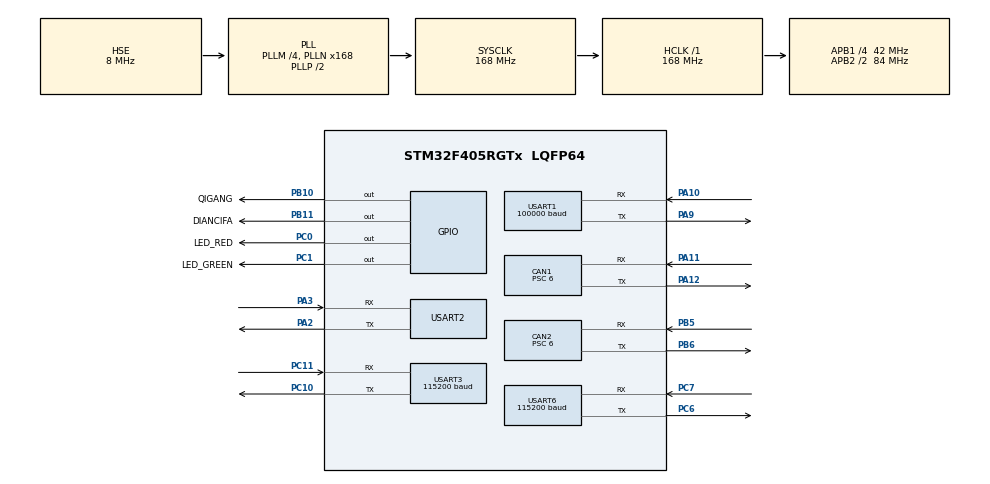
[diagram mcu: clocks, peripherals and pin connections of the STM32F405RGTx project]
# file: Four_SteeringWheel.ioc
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CAN1.BS1=CAN_BS1_3TQ
CAN1.BS2=CAN_BS2_3TQ
CAN1.CalculateBaudRate=1000000
CAN1.CalculateTimeBit=1000
CAN1.CalculateTimeQuantum=142.85714285714286
CAN1.Prescaler=6
CAN2.BS1=CAN_BS1_3TQ
CAN2.BS2=CAN_BS2_3TQ
CAN2.CalculateBaudRate=1000000
CAN2.CalculateTimeBit=1000
CAN2.CalculateTimeQuantum=142.85714285714286
CAN2.Prescaler=6
Dma.Request0=USART1_RX
Dma.Request1=USART2_RX
Dma.Request2=USART2_TX
Dma.Request3=USART3_RX
Dma.Request4=USART3_TX
Dma.Request5=USART6_RX
Dma.Request6=USART6_TX
Dma.USART1_RX.0.Direction=DMA_PERIPH_TO_MEMORY
Dma.USART1_RX.0.FIFOMode=DMA_FIFOMODE_DISABLE
Dma.USART1_RX.0.Instance=DMA2_Stream2
Dma.USART1_RX.0.MemDataAlignment=DMA_MDATAALIGN_BYTE
Dma.USART1_RX.0.MemInc=DMA_MINC_ENABLE
Dma.USART1_RX.0.Mode=DMA_CIRCULAR
Dma.USART1_RX.0.PeriphDataAlignment=DMA_PDATAALIGN_BYTE
Dma.USART1_RX.0.PeriphInc=DMA_PINC_DISABLE
Dma.USART1_RX.0.Priority=DMA_PRIORITY_LOW
Dma.USART2_RX.1.Direction=DMA_PERIPH_TO_MEMORY
Dma.USART2_RX.1.FIFOMode=DMA_FIFOMODE_DISABLE
Dma.USART2_RX.1.Instance=DMA1_Stream5
Dma.USART2_RX.1.MemDataAlignment=DMA_MDATAALIGN_BYTE
Dma.USART2_RX.1.MemInc=DMA_MINC_ENABLE
Dma.USART2_RX.1.Mode=DMA_CIRCULAR
Dma.USART2_RX.1.PeriphDataAlignment=DMA_PDATAALIGN_BYTE
Dma.USART2_RX.1.PeriphInc=DMA_PINC_DISABLE
Dma.USART2_RX.1.Priority=DMA_PRIORITY_LOW
Dma.USART2_TX.2.Direction=DMA_MEMORY_TO_PERIPH
Dma.USART2_TX.2.FIFOMode=DMA_FIFOMODE_DISABLE
Dma.USART2_TX.2.Instance=DMA1_Stream6
Dma.USART2_TX.2.MemDataAlignment=DMA_MDATAALIGN_BYTE
Dma.USART2_TX.2.MemInc=DMA_MINC_ENABLE
Dma.USART2_TX.2.Mode=DMA_CIRCULAR
Dma.USART2_TX.2.PeriphDataAlignment=DMA_PDATAALIGN_BYTE
Dma.USART2_TX.2.PeriphInc=DMA_PINC_DISABLE
Dma.USART2_TX.2.Priority=DMA_PRIORITY_LOW
Dma.USART3_RX.3.Direction=DMA_PERIPH_TO_MEMORY
Dma.USART3_RX.3.FIFOMode=DMA_FIFOMODE_DISABLE
Dma.USART3_RX.3.Instance=DMA1_Stream1
Dma.USART3_RX.3.MemDataAlignment=DMA_MDATAALIGN_BYTE
Dma.USART3_RX.3.MemInc=DMA_MINC_ENABLE
Dma.USART3_RX.3.Mode=DMA_CIRCULAR
Dma.USART3_RX.3.PeriphDataAlignment=DMA_PDATAALIGN_BYTE
Dma.USART3_RX.3.PeriphInc=DMA_PINC_DISABLE
Dma.USART3_RX.3.Priority=DMA_PRIORITY_LOW
Dma.USART3_TX.4.Direction=DMA_MEMORY_TO_PERIPH
Dma.USART3_TX.4.FIFOMode=DMA_FIFOMODE_DISABLE
Dma.USART3_TX.4.Instance=DMA1_Stream3
Dma.USART3_TX.4.MemDataAlignment=DMA_MDATAALIGN_BYTE
Dma.USART3_TX.4.MemInc=DMA_MINC_ENABLE
Dma.USART3_TX.4.Mode=DMA_CIRCULAR
Dma.USART3_TX.4.PeriphDataAlignment=DMA_PDATAALIGN_BYTE
Dma.USART3_TX.4.PeriphInc=DMA_PINC_DISABLE
Dma.USART3_TX.4.Priority=DMA_PRIORITY_LOW
Dma.USART6_RX.5.Direction=DMA_PERIPH_TO_MEMORY
Dma.USART6_RX.5.FIFOMode=DMA_FIFOMODE_DISABLE
Dma.USART6_RX.5.Instance=DMA2_Stream1
Dma.USART6_RX.5.MemDataAlignment=DMA_MDATAALIGN_BYTE
Dma.USART6_RX.5.MemInc=DMA_MINC_ENABLE
Dma.USART6_RX.5.Mode=DMA_CIRCULAR
Dma.USART6_RX.5.PeriphDataAlignment=DMA_PDATAALIGN_BYTE
Dma.USART6_RX.5.PeriphInc=DMA_PINC_DISABLE
Dma.USART6_RX.5.Priority=DMA_PRIORITY_LOW
Dma.USART6_TX.6.Direction=DMA_MEMORY_TO_PERIPH
Dma.USART6_TX.6.FIFOMode=DMA_FIFOMODE_DISABLE
Dma.USART6_TX.6.Instance=DMA2_Stream6
Dma.USART6_TX.6.MemDataAlignment=DMA_MDATAALIGN_BYTE
Dma.USART6_TX.6.MemInc=DMA_MINC_ENABLE
Dma.USART6_TX.6.Mode=DMA_CIRCULAR
Dma.USART6_TX.6.PeriphDataAlignment=DMA_PDATAALIGN_BYTE
Dma.USART6_TX.6.PeriphInc=DMA_PINC_DISABLE
Dma.USART6_TX.6.Priority=DMA_PRIORITY_LOW
Mcu.Family=STM32F4
Mcu.Name=STM32F405RGTx
Mcu.Package=LQFP64
NVIC.CAN1_RX0_IRQn=true\:5\:0\:true\:false\:true\:true\:true
NVIC.CAN2_RX0_IRQn=true\:5\:0\:true\:false\:true\:true\:true
NVIC.DMA1_Stream1_IRQn=true\:0\:0\:false\:false\:true\:false\:true
NVIC.DMA1_Stream3_IRQn=true\:0\:0\:false\:false\:true\:false\:true
NVIC.DMA1_Stream5_IRQn=true\:0\:0\:false\:false\:true\:false\:true
NVIC.DMA1_Stream6_IRQn=true\:0\:0\:false\:false\:true\:false\:true
NVIC.DMA2_Stream1_IRQn=true\:0\:0\:false\:false\:true\:false\:true
NVIC.DMA2_Stream2_IRQn=true\:0\:0\:false\:false\:true\:false\:true
NVIC.DMA2_Stream6_IRQn=true\:0\:0\:false\:false\:true\:false\:true
NVIC.PriorityGroup=NVIC_PRIORITYGROUP_4
NVIC.TIM2_IRQn=true\:5\:0\:true\:false\:true\:true\:true
NVIC.USART1_IRQn=true\:0\:0\:true\:false\:true\:true\:true
NVIC.USART2_IRQn=true\:5\:0\:true\:false\:true\:true\:true
NVIC.USART3_IRQn=true\:0\:0\:false\:false\:true\:true\:true
NVIC.USART6_IRQn=true\:0\:0\:false\:false\:true\:true\:true
PA10.Mode=Asynchronous
PA10.Signal=USART1_RX
PA11.Mode=CAN_Activate
PA11.Signal=CAN1_RX
PA12.Mode=CAN_Activate
PA12.Signal=CAN1_TX
PA13.Mode=Serial_Wire
PA13.Signal=SYS_JTMS-SWDIO
PA14.Mode=Serial_Wire
PA14.Signal=SYS_JTCK-SWCLK
PA2.Mode=Asynchronous
PA2.Signal=USART2_TX
PA3.Mode=Asynchronous
PA3.Signal=USART2_RX
PA9.Mode=Asynchronous
PA9.Signal=USART1_TX
PB10.GPIO_Label=QIGANG
PB10.GPIO_PuPd=GPIO_PULLUP
PB10.Signal=GPIO_Output
PB11.GPIO_Label=DIANCIFA
PB11.GPIO_PuPd=GPIO_PULLUP
PB11.Signal=GPIO_Output
PB5.Mode=CAN_Activate
PB5.Signal=CAN2_RX
PB6.Mode=CAN_Activate
PB6.Signal=CAN2_TX
PC0.GPIO_Label=LED_RED
PC0.GPIO_PuPd=GPIO_PULLUP
PC0.Signal=GPIO_Output
PC1.GPIO_Label=LED_GREEN
PC1.GPIO_PuPd=GPIO_PULLUP
PC1.Signal=GPIO_Output
PC10.Mode=Asynchronous
PC10.Signal=USART3_TX
PC11.Mode=Asynchronous
PC11.Signal=USART3_RX
PC6.Mode=Asynchronous
PC6.Signal=USART6_TX
PC7.Mode=Asynchronous
PC7.Signal=USART6_RX
PH0-OSC_IN.Mode=HSE-External-Oscillator
PH0-OSC_IN.Signal=RCC_OSC_IN
PH1-OSC_OUT.Mode=HSE-External-Oscillator
PH1-OSC_OUT.Signal=RCC_OSC_OUT
ProjectManager.HeapSize=0x200
ProjectManager.StackSize=0x400
ProjectManager.TargetToolchain=MDK-ARM V5.27
RCC.48MHZClocksFreq_Value=84000000
RCC.AHBFreq_Value=168000000
RCC.APB1CLKDivider=RCC_HCLK_DIV4
RCC.APB1Freq_Value=42000000
RCC.APB1TimFreq_Value=84000000
RCC.APB2CLKDivider=RCC_HCLK_DIV2
RCC.APB2Freq_Value=84000000
RCC.APB2TimFreq_Value=168000000
RCC.CortexFreq_Value=168000000
RCC.HCLKFreq_Value=168000000
RCC.HSE_VALUE=8000000
RCC.HSI_VALUE=16000000
RCC.LSE_VALUE=32768
RCC.PLLM=4
RCC.PLLN=168
RCC.PLLSourceVirtual=RCC_PLLSOURCE_HSE
RCC.SYSCLKFreq_VALUE=168000000
RCC.SYSCLKSource=RCC_SYSCLKSOURCE_PLLCLK
RCC.VCOOutputFreq_Value=336000000
TIM2.Period=1000-1
TIM2.Prescaler=84-1
USART1.BaudRate=100000
USART1.Parity=PARITY_EVEN
USART1.VirtualMode=VM_ASYNC
USART1.WordLength=WORDLENGTH_9B
USART2.VirtualMode=VM_ASYNC
USART3.BaudRate=115200
USART3.VirtualMode=VM_ASYNC
USART6.BaudRate=115200
USART6.VirtualMode=VM_ASYNC
VP_TIM2_VS_ClockSourceINT.Mode=Internal
board=custom

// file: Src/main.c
/* USER CODE BEGIN Header */
/**
  ******************************************************************************
  * @file           : main.c
  * @brief          : Main program body
  ******************************************************************************
  * @attention
  *
  * <h2><center>&copy; Copyright (c) 2021 STMicroelectronics.
  * All rights reserved.</center></h2>
  *
  * This software component is licensed by ST under BSD 3-Clause license,
  * the "License"; You may not use this file except in compliance with the
  * License. You may obtain a copy of the License at:
  *                        opensource.org/licenses/BSD-3-Clause
  *
  ******************************************************************************
  */
/* USER CODE END Header */
#include "main.h"
#include "can.h"
#include "dma.h"
#include "tim.h"
#include "usart.h"
#include "gpio.h"

/* USER CODE BEGIN Includes */
#include "math.h"
#include "Chassis_task.h"
/* USER CODE END Includes */

void SystemClock_Config(void);

int main(void)
{
  /* USER CODE BEGIN 1 */
extern uint8_t led_data[8];
  /* USER CODE END 1 */

  /* MCU Configuration--------------------------------------------------------*/

  /* Reset of all peripherals, Initializes the Flash interface and the Systick. */
  HAL_Init();

  /* Configure the system clock */
  SystemClock_Config();

  /* Initialize all configured peripherals */
  MX_GPIO_Init();
  MX_DMA_Init();
  MX_CAN1_Init();
  MX_USART1_UART_Init();
  MX_TIM2_Init();
  MX_CAN2_Init();
  MX_USART2_UART_Init();
  MX_USART3_UART_Init();
  MX_USART6_UART_Init();
  /* USER CODE BEGIN 2 */
	ALL_Init();
//	HAL_UART_Transmit_DMA(&huart3,led_data,11);
//	HAL_UART_Transmit_DMA(&huart6,led_data,11);
  /* USER CODE END 2 */

  /* Infinite loop */
  while (1)
  {

  }
}

void SystemClock_Config(void)
{
  RCC_OscInitTypeDef RCC_OscInitStruct = {0};
  RCC_ClkInitTypeDef RCC_ClkInitStruct = {0};

  /** Configure the main internal regulator output voltage
  */
  __HAL_RCC_PWR_CLK_ENABLE();
  __HAL_PWR_VOLTAGESCALING_CONFIG(PWR_REGULATOR_VOLTAGE_SCALE1);
  /** Initializes the RCC Oscillators according to the specified parameters
  * in the RCC_OscInitTypeDef structure.
  */
  RCC_OscInitStruct.OscillatorType = RCC_OSCILLATORTYPE_HSE;
  RCC_OscInitStruct.HSEState = RCC_HSE_ON;
  RCC_OscInitStruct.PLL.PLLState = RCC_PLL_ON;
  RCC_OscInitStruct.PLL.PLLSource = RCC_PLLSOURCE_HSE;
  RCC_OscInitStruct.PLL.PLLM = 4;
  RCC_OscInitStruct.PLL.PLLN = 168;
  RCC_OscInitStruct.PLL.PLLP = RCC_PLLP_DIV2;
  RCC_OscInitStruct.PLL.PLLQ = 4;
  if (HAL_RCC_OscConfig(&RCC_OscInitStruct) != HAL_OK)
  {
    Error_Handler();
  }
  /** Initializes the CPU, AHB and APB buses clocks
  */
  RCC_ClkInitStruct.ClockType = RCC_CLOCKTYPE_HCLK|RCC_CLOCKTYPE_SYSCLK
                              |RCC_CLOCKTYPE_PCLK1|RCC_CLOCKTYPE_PCLK2;
  RCC_ClkInitStruct.SYSCLKSource = RCC_SYSCLKSOURCE_PLLCLK;
  RCC_ClkInitStruct.AHBCLKDivider = RCC_SYSCLK_DIV1;
  RCC_ClkInitStruct.APB1CLKDivider = RCC_HCLK_DIV4;
  RCC_ClkInitStruct.APB2CLKDivider = RCC_HCLK_DIV2;

  if (HAL_RCC_ClockConfig(&RCC_ClkInitStruct, FLASH_LATENCY_5) != HAL_OK)
  {
    Error_Handler();
  }
}

void Error_Handler(void)
{
  __disable_irq();
  while (1)
  {
  }
}

/************************ (C) COPYRIGHT STMicroelectronics *****END OF FILE****/
